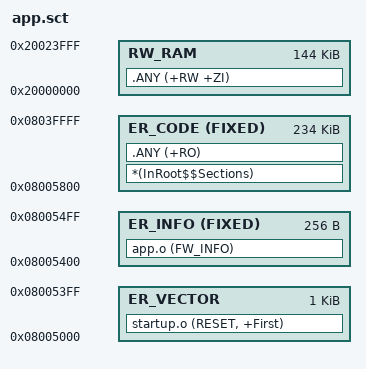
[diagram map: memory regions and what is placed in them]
LR_APP 0x08005000 0x3B000 {
 ER_VECTOR 0x08005000 0x400 { startup.o (RESET, +First) }
 ER_INFO 0x08005400 FIXED 0x100 { app.o (FW_INFO) }
 ER_CODE 0x08005800 FIXED 0x3A800 {
  *(InRoot$$Sections)
  .ANY (+RO)
 }
 RW_RAM 0x20000000 0x24000 { .ANY (+RW +ZI) }
}
